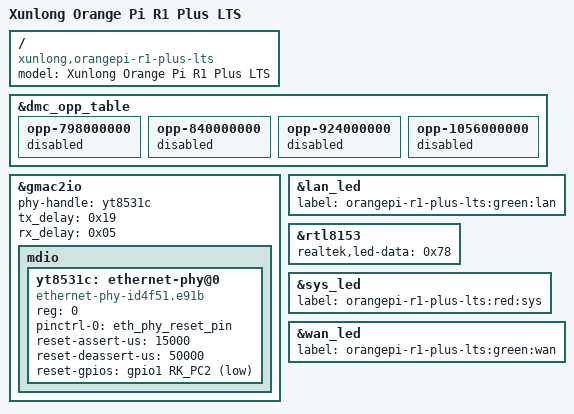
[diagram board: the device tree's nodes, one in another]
// SPDX-License-Identifier: (GPL-2.0+ OR MIT)
/*
 * Copyright (c) 2016 Xunlong Software. Co., Ltd.
 * (http://www.orangepi.org)
 *
 * Copyright (c) 2021 Tianling Shen <cnsztl@immortalwrt.org>
 */

#include "rk3328-orangepi-r1-plus.dts"

/ {
	model = "Xunlong Orange Pi R1 Plus LTS";
	compatible = "xunlong,orangepi-r1-plus-lts", "rockchip,rk3328";
};

&dmc_opp_table {
	opp-798000000 {
		status = "disabled";
	};
	opp-840000000 {
		status = "disabled";
	};
	opp-924000000 {
		status = "disabled";
	};
	opp-1056000000 {
		status = "disabled";
	};
};

&gmac2io {
	phy-handle = <&yt8531c>;
	tx_delay = <0x19>;
	rx_delay = <0x05>;

	mdio {
		/delete-node/ ethernet-phy@1;

		yt8531c: ethernet-phy@0 {
			compatible = "ethernet-phy-id4f51.e91b",
				     "ethernet-phy-ieee802.3-c22";
			reg = <0>;
			pinctrl-0 = <&eth_phy_reset_pin>;
			pinctrl-names = "default";
			reset-assert-us = <15000>;
			reset-deassert-us = <50000>;
			reset-gpios = <&gpio1 RK_PC2 GPIO_ACTIVE_LOW>;
		};
	};
};

&lan_led {
	label = "orangepi-r1-plus-lts:green:lan";
};

&rtl8153 {
	realtek,led-data = <0x78>;
};

&sys_led {
	label = "orangepi-r1-plus-lts:red:sys";
};

&wan_led {
	label = "orangepi-r1-plus-lts:green:wan";
};
